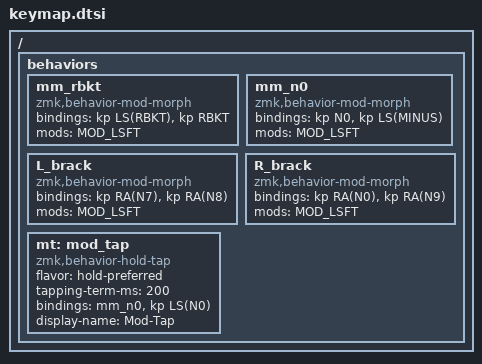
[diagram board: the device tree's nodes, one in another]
#include <behaviors.dtsi>
#include <dt-bindings/zmk/keys.h>
#include <dt-bindings/zmk/bt.h>

/ {
    behaviors {
        mm_rbkt: mm_rbkt {
            compatible = "zmk,behavior-mod-morph";
            #binding-cells = <0>;
            bindings = <&kp LS(RBKT)>, <&kp RBKT>;
            mods = <MOD_LSFT>;
        };
        mm_n0: mm_n0 {
            compatible = "zmk,behavior-mod-morph";
            #binding-cells = <0>;
            bindings = <&kp N0>, <&kp LS(MINUS)>;
            mods = <MOD_LSFT>;
        };
        L_brack: L_brack {
            compatible = "zmk,behavior-mod-morph";
            #binding-cells = <0>;
            bindings = <&kp RA(N7)>, <&kp RA(N8)>;
            mods = <MOD_LSFT>;
        };

        R_brack: R_brack {
            compatible = "zmk,behavior-mod-morph";
            #binding-cells = <0>;
            bindings = <&kp RA(N0)>, <&kp RA(N9)>;
            mods = <MOD_LSFT>;
        };

        mt: mod_tap {
            compatible = "zmk,behavior-hold-tap";
            #binding-cells = <11>;
            flavor = "hold-preferred";
            tapping-term-ms = <200>;
            bindings = <&mm_n0>, <&kp LS(N0)>;
            display-name = "Mod-Tap";
        };
    };
};
